# lm3s9b92 register map
Vendor: Texas Instruments Inc.; Series: LM3S; File version: 1.2
CPU: CM3 r2p0, little endian, no MPU, no FPU, 3 interrupt priority bits
Registers are 32-bit, read-write, reset 0x0 unless marked. A register's access mark holds for its fields unless they carry their own. Offsets are from the block's base; [hi:lo] are bit positions; {n}, {i} and the like mark numbered series.

## GPIOA — Register map for GPIO PORT A peripheral.
Base 0x40004000
Same registers: GPIOB 0x40005000, GPIOC 0x40006000, GPIOD 0x40007000, GPIOE 0x40024000, GPIOF 0x40025000, GPIOG 0x40026000, GPIOH 0x40027000, GPIOJ 0x4003D000
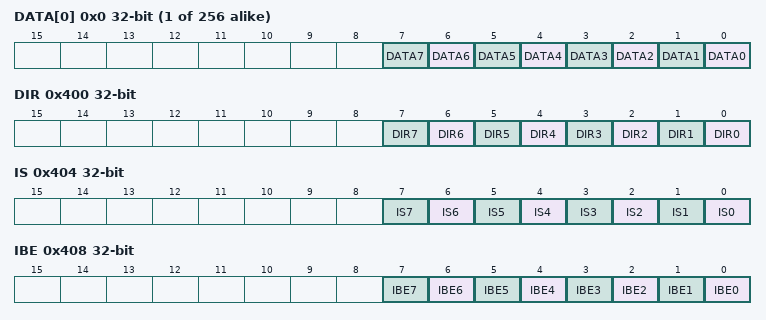
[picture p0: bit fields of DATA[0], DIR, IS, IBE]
{0x0+4i} DATA[{i}] (i=0..255) (reset mask 0xFF) — Data of GPIO Port.
  [n] DATA{n} (n=0..7) — GPIO Port single-pin data.
    on write: 1=PIN_SET (Set output pin high.); 0=PIN_RESET (Set output pin low.) | on read: 1=PIN_SET (Input pin set high.); 0=PIN_RESET (Input pin set low.)
0x400 DIR (reset mask 0xFF) — Directions of GPIO Port pins.
  [n] DIR{n} (n=0..7) — GPIO Port pin directions.
    on write: 1=PIN_OUTPUT (Set pin to output.); 0=PIN_INPUT (Set pin to input.) | on read: 1=PIN_OUTPUT (Pin set as output.); 0=PIN_INPUT (Pin set as input.)
0x404 IS (reset mask 0xFF) — GPIO Interrupt Sense.
  [n] IS{n} (n=0..7) — GPIO Port pin interrupt sensitivity.
    on write: 1=PIN_IRQ_LEVEL (Set pin interrupt sensitivity to level.); 0=PIN_IRQ_EDGE (Set pin interrupt sensitivity to edge.) | on read: 1=PIN_IRQ_LEVEL (Pin interrupt sensitivity set to level.); 0=PIN_IRQ_EDGE (Pin interrupt sensitivity set to edge.)
0x408 IBE (reset mask 0xFF) — GPIO Interrupt Both Edges Sensitivity.
  [n] IBE{n} (n=0..7) — GPIO Port pin interrupt both edges sensitivity.
    1=PIN_IRQ_SENS_BOTH_EDGES (Both edges on the corresponding pin trigger an interrupt.); 0=PIN_IRQ_SENS_IEV (Interrupt generation is controlled by the GPIOIEV register.)
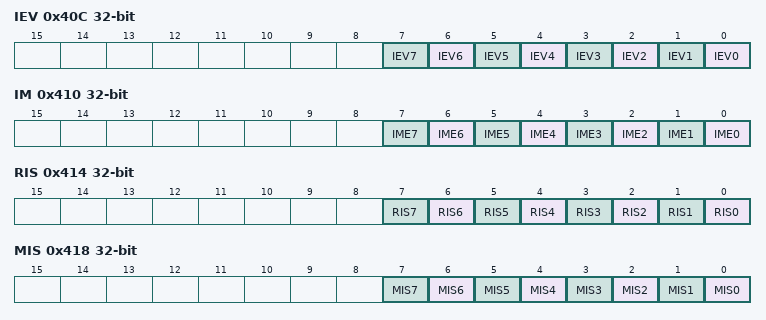
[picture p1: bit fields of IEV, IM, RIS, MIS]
0x40C IEV (reset mask 0xFF) — GPIO Interrupt Event.
  [n] IEV{n} (n=0..7) — GPIO Port pin interrupt event selection.
    1=PIN_IRQ_TRIG_RISING_EDGE (A rising edge or a High level on the corresponding pin triggers an interrupt.); 0=PIN_IRQ_TRIG_FALLING_EDGE (A falling edge or a Low level on the corresponding pin triggers an interrupt.)
0x410 IM (reset mask 0xFF) — GPIO Interrupt Mask.
  [n] IME{n} (n=0..7) — GPIO Port interrupt mask.
    1=PIN_IRQ_UNMASKED_PIN (The interrupt from the corresponding pin is sent to the interrupt controller.); 0=PIN_IRQ_MASKED_PIN (The interrupt from the corresponding pin is masked.)
0x414 RIS ro (reset mask 0xFF) — GPIO Raw Interrupt Status.
  [n] RIS{n} (n=0..7) — GPIO Port pin raw interrupt status.
    on read: 1=PIN_IRQ_PIN_RAW_STATUS_TRUE (An interrupt condition has occurred on the corresponding pin.); 0=PIN_IRQ_PIN_RAW_STATUS_FALSE (An interrupt condition has not occurred on the corresponding pin.)
0x418 MIS ro (reset mask 0xFF) — GPIO Mask Interrupt Status.
  [n] MIS{n} (n=0..7) — GPIO Port pin masked interrupt status.
    on read: 1=PIN_IRQ_PIN_MASK_STATUS_TRUE (An interrupt condition on the corresponding pin has triggered an interrupt to the interrupt controller.); 0=PIN_IRQ_PIN_MASK_STATUS_FALSE (An interrupt condition on the corresponding pin is masked or has not occurred.)
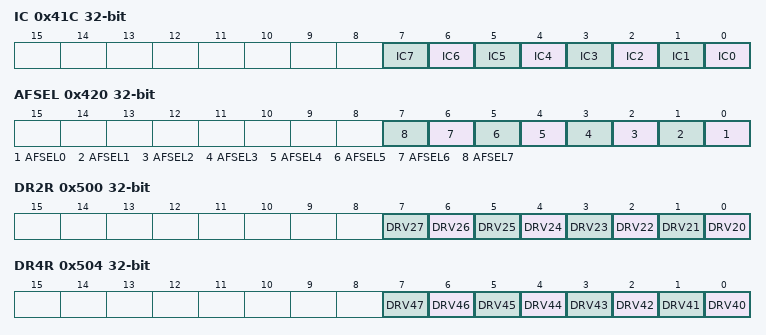
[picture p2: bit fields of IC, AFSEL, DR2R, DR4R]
0x41C IC wo (reset mask 0xFF) — GPIO Interrupt Clear.
  [n] IC{n} (n=0..7) write-1-clears — GPIO Port pin interrupt clear.
    on write: 1=PIN_IRQ_CLR (The corresponding interrupt is cleared.); 0=PIN_IRQ_NOP (The corresponding interrupt is unaffected.)
0x420 AFSEL (reset mask 0xFF) — GPIO Alternate Function Select.
  [n] AFSEL{n} (n=0..7) — GPIO Port pin alternate function select.
    1=PIN_AF (The associated pin functions as a peripheral signal and is controlled by the alternate hardware function.); 0=PIN_GP (The associated pin functions as a GPIO and is controlled by the GPIO registers.)
0x500 DR2R (reset mask 0xFF) — GPIO 2-mA Drive Select.
  [n] DRV2{n} (n=0..7) — GPIO Port pin output pad 2-mA drive enable.
    1=PIN_OUTPUT_2MA (The corresponding GPIO pin has 2-mA drive.); 0=PIN_2MA_INACTIVE (The drive for the corresponding GPIO pin is controlled by the GPIODR4R or GPIODR8R register.)
0x504 DR4R (reset mask 0xFF) — GPIO 4-mA Drive Select.
  [n] DRV4{n} (n=0..7) — GPIO Port pin output pad 4-mA drive enable.
    1=PIN_OUTPUT_4MA (The corresponding GPIO pin has 4-mA drive.); 0=PIN_4MA_INACTIVE (The drive for the corresponding GPIO pin is controlled by the GPIODR2R or GPIODR8R register.)
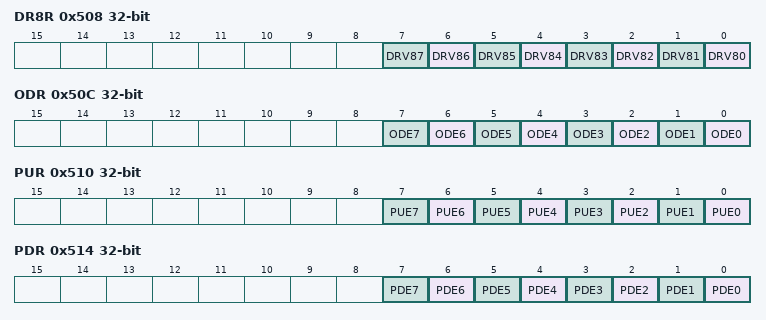
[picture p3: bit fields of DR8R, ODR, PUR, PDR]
0x508 DR8R (reset mask 0xFF) — GPIO 8-mA Drive Select.
  [n] DRV8{n} (n=0..7) — GPIO Port pin output pad 8-mA drive enable.
    1=PIN_OUTPUT_8MA (The corresponding GPIO pin has 8-mA drive.); 0=PIN_8MA_INACTIVE (The drive for the corresponding GPIO pin is controlled by the GPIODR2R or GPIODR4R register.)
0x50C ODR (reset mask 0xFF) — GPIO Open Drain Select.
  [n] ODE{n} (n=0..7) — Output Pad Open Drain Enable.
    1=PIN_OUTPUT_OD_ON (The corresponding pin is configured as open drain.); 0=PIN_OUTPUT_OD_OFF (The corresponding pin is not configured as open drain.)
0x510 PUR (reset mask 0xFF) — GPIO Pull-Up Select.
  [n] PUE{n} (n=0..7) — Pad Weak Pull-Up Enable.
    1=PIN_PULL_UP_WEAK (The corresponding pin has a weak pull-up resistor.); 0=PIN_PULL_UP_OFF (The corresponding pin is not affected.)
0x514 PDR (reset mask 0xFF) — GPIO Pull-Down Select.
  [n] PDE{n} (n=0..7) — Pad Weak Pull-Down Enable.
    1=PIN_PULL_DOWN_WEAK (The corresponding pin has a weak pull-down resistor.); 0=PIN_PULL_DOWN_OFF (The corresponding pin is not affected.)
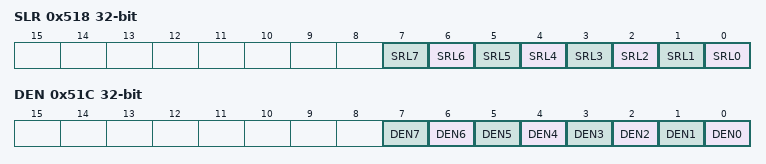
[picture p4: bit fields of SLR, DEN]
0x518 SLR (reset mask 0xFF) — GPIO Slew Rate Control Select.
  [n] SRL{n} (n=0..7) — Slew Rate Limit Enable (8-mA drive only).
    1=PIN_SLEW_RATE_ON (Slew rate control is enabled for the corresponding pin.); 0=PIN_SLEW_RATE_OFF (Slew rate control is disabled for the corresponding pin.)
0x51C DEN (reset mask 0xFF) — GPIO Digital Enable.
  [n] DEN{n} (n=0..7) — Digital Enable.
    1=PIN_DIGITAL_FUNC_ON (The digital functions for the corresponding pin are enabled.); 0=PIN_DIGITAL_FUNC_OFF (The digital functions for the corresponding pin are disabled.)

## SYSCTL — System control configures the overall operation of the device and provides information about the device.
Base 0x400FE000
0x00 DID0 ro reset 0x10040000 — This register identifies the version of the microcontroller.
  [30:28] VER — DID0 Version.
    1=DID0VER (Second version of the DID0 register format.)
